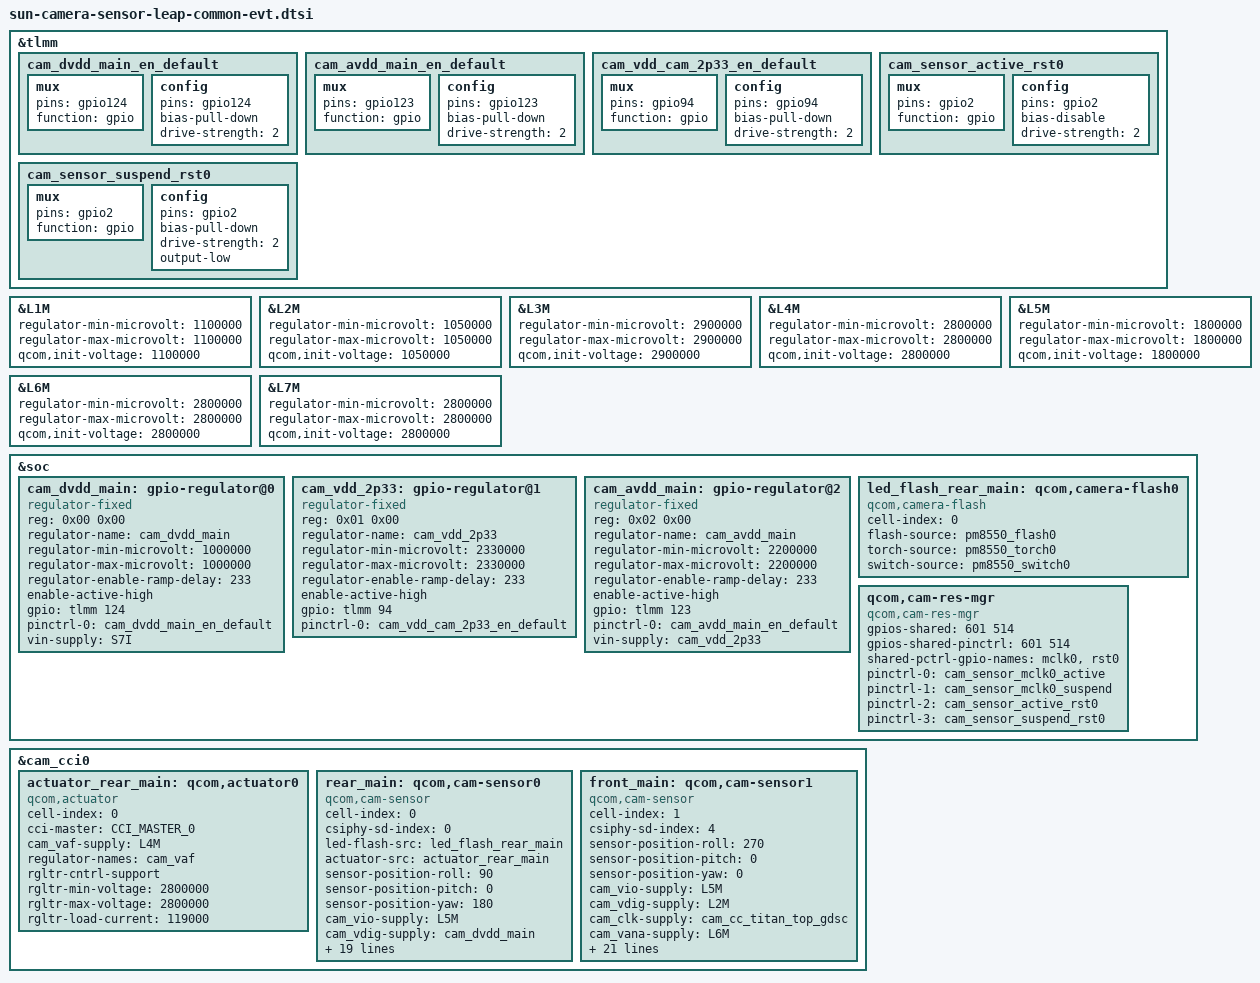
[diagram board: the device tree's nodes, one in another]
#include <dt-bindings/msm-camera.h>

&tlmm {

	cam_dvdd_main_en_default: cam_dvdd_main_en_default {
		mux {
			pins = "gpio124";
			function = "gpio";
		};

		config {
			pins = "gpio124";
			bias-pull-down; /* PULL DOWN */
			drive-strength = <2>; /* 2 MA */
		};
	};

	cam_avdd_main_en_default: cam_avdd_main_en_default {
		mux {
			pins = "gpio123";
			function = "gpio";
		};

		config {
			pins = "gpio123";
			bias-pull-down; /* PULL DOWN */
			drive-strength = <2>; /* 2 MA */
		};
	};

	cam_vdd_cam_2p33_en_default: cam_vdd_cam_2p33_en_default {
		mux {
			pins = "gpio94";
			function = "gpio";
		};

		config {
			pins = "gpio94";
			bias-pull-down; /* PULL DOWN */
			drive-strength = <2>; /* 2 MA */
		};
	};

	cam_sensor_active_rst0: cam_sensor_active_rst0 {
		mux {
			pins = "gpio2";
			function = "gpio";
		};

		config {
			pins = "gpio2";
			bias-disable; /* No PULL */
			drive-strength = <2>; /* 2 MA */
		};
	};

	cam_sensor_suspend_rst0: cam_sensor_suspend_rst0 {
		mux {
			pins = "gpio2";
			function = "gpio";
		};

		config {
			pins = "gpio2";
			bias-pull-down; /* PULL DOWN */
			drive-strength = <2>; /* 2 MA */
			output-low;
		};
	};
};
/*
&L1I {
	regulator-min-microvolt = <1800000>;
	regulator-max-microvolt = <1800000>;
	qcom,init-voltage = <1800000>;
};
*/
&L1M {
	regulator-min-microvolt = <1100000>;
	regulator-max-microvolt = <1100000>;
	qcom,init-voltage = <1100000>;
};

&L2M {
	regulator-min-microvolt = <1050000>;
	regulator-max-microvolt = <1050000>;
	qcom,init-voltage = <1050000>;
};

&L3M {
	regulator-min-microvolt = <2900000>;
	regulator-max-microvolt = <2900000>;
	qcom,init-voltage = <2900000>;
};

&L4M {
	regulator-min-microvolt = <2800000>;
	regulator-max-microvolt = <2800000>;
	qcom,init-voltage = <2800000>;
};

&L5M {
	regulator-min-microvolt = <1800000>;
	regulator-max-microvolt = <1800000>;
	qcom,init-voltage = <1800000>;
};

&L6M {
	regulator-min-microvolt = <2800000>;
	regulator-max-microvolt = <2800000>;
	qcom,init-voltage = <2800000>;
};

&L7M {
	regulator-min-microvolt = <2800000>;
	regulator-max-microvolt = <2800000>;
	qcom,init-voltage = <2800000>;
};

&soc {
	cam_dvdd_main: gpio-regulator@0 {
		compatible = "regulator-fixed";
		reg = <0x00 0x00>;
		regulator-name = "cam_dvdd_main";
		regulator-min-microvolt = <1000000>;
		regulator-max-microvolt = <1000000>;
		regulator-enable-ramp-delay = <233>;
		enable-active-high;
		gpio = <&tlmm 124 0>;
		pinctrl-names = "default";
		pinctrl-0 = <&cam_dvdd_main_en_default>;
		vin-supply = <&S7I>;
	};

	cam_vdd_2p33: gpio-regulator@1 {
		compatible = "regulator-fixed";
		reg = <0x01 0x00>;
		regulator-name = "cam_vdd_2p33";
		regulator-min-microvolt = <2330000>;
		regulator-max-microvolt = <2330000>;
		regulator-enable-ramp-delay = <233>;
		enable-active-high;
		//regulator-always-on;
		gpio = <&tlmm 94 0>;
		pinctrl-names = "default";
		pinctrl-0 = <&cam_vdd_cam_2p33_en_default>;
		//vin-supply = <&BOB1>;
	};

	cam_avdd_main: gpio-regulator@2 {
		compatible = "regulator-fixed";
		reg = <0x02 0x00>;
		regulator-name = "cam_avdd_main";
		regulator-min-microvolt = <2200000>;
		regulator-max-microvolt = <2200000>;
		regulator-enable-ramp-delay = <233>;
		enable-active-high;
		gpio = <&tlmm 123 0>;
		pinctrl-names = "default";
		pinctrl-0 = <&cam_avdd_main_en_default>;
		vin-supply = <&cam_vdd_2p33>;
	};

	led_flash_rear_main: qcom,camera-flash0 {
		cell-index = <0>;
		compatible = "qcom,camera-flash";
		flash-source = <&pm8550_flash0>;
		torch-source = <&pm8550_torch0>;
		switch-source = <&pm8550_switch0>;
		status = "ok";
	};

	qcom,cam-res-mgr {
		compatible = "qcom,cam-res-mgr";
		gpios-shared = <601 514>;
		gpios-shared-pinctrl = <601 514>;
		shared-pctrl-gpio-names = "mclk0", "rst0";
		pinctrl-names = "mclk0_active", "mclk0_suspend", "rst0_active", "rst0_suspend";
		pinctrl-0 = <&cam_sensor_mclk0_active>;
		pinctrl-1 = <&cam_sensor_mclk0_suspend>;
		pinctrl-2 = <&cam_sensor_active_rst0>;
		pinctrl-3 = <&cam_sensor_suspend_rst0>;
		status = "ok";
	};
};

&cam_cci0 {
	actuator_rear_main: qcom,actuator0 {
		cell-index = <0>;
		compatible = "qcom,actuator";
		cci-master = <CCI_MASTER_0>;
		cam_vaf-supply = <&L4M>;
		regulator-names = "cam_vaf";
		rgltr-cntrl-support;
		rgltr-min-voltage = <2800000>;
		rgltr-max-voltage = <2800000>;
		rgltr-load-current = <119000>;
		status = "ok";
	};

	rear_main: qcom,cam-sensor0 {
		cell-index = <0>;
		compatible = "qcom,cam-sensor";
		csiphy-sd-index = <0>;
		//eeprom-src = <&eeprom_rear_main>;
		led-flash-src = <&led_flash_rear_main>;
		actuator-src = <&actuator_rear_main>;
		sensor-position-roll = <90>;
		sensor-position-pitch = <0>;
		sensor-position-yaw = <180>;
		cam_vio-supply = <&L5M>;
		cam_vdig-supply = <&cam_dvdd_main>;
		cam_clk-supply = <&cam_cc_titan_top_gdsc>;
		cam_vana-supply = <&cam_avdd_main>;
		regulator-names = "cam_vio",
			"cam_vdig","cam_clk","cam_vana";
		rgltr-cntrl-support;
		rgltr-min-voltage = <1800000 1000000 0 2200000>;
		rgltr-max-voltage = <1800000 1000000 0 2200000>;
		rgltr-load-current = <101000 787000 0 1000>;
		gpio-no-mux = <0>;
		//pinctrl-names = "cam_default", "cam_suspend";
		//pinctrl-0 = <&cam_sensor_mclk0_active
		//	&cam_sensor_active_rst0>;
		//pinctrl-1 = <&cam_sensor_mclk0_suspend
		//	&cam_sensor_suspend_rst0>;
		gpios = <&tlmm 89 0>,
			<&tlmm 2 0>;
		gpio-reset = <1>;
		gpio-req-tbl-num = <0 1>;
		gpio-req-tbl-flags = <1 0>;
		gpio-req-tbl-label = "CAMIF_MCLK0",
					"CAM_RESET0";
		cci-master = <CCI_MASTER_0>;
		clocks = <&cambistmclkcc CAM_BIST_MCLK_CC_MCLK0_CLK>;
		clock-names = "cam_clk";
		clock-cntl-level = "nominal";
		clock-rates = <24000000>;
		status = "ok";
	};

	front_main: qcom,cam-sensor1 {
		cell-index = <1>;
		compatible = "qcom,cam-sensor";
		csiphy-sd-index = <4>;
		//eeprom-src = <&eeprom_front>;
		sensor-position-roll = <270>;
		sensor-position-pitch = <0>;
		sensor-position-yaw = <0>;
		cam_vio-supply = <&L5M>;
		cam_vdig-supply = <&L2M>;
		cam_clk-supply = <&cam_cc_titan_top_gdsc>;
		cam_vana-supply = <&L6M>;
		regulator-names = "cam_vio", "cam_vdig","cam_clk", "cam_vana";
		rgltr-cntrl-support;
		rgltr-min-voltage = <1800000 1050000 0 2800000>;
		rgltr-max-voltage = <1800000 1050000 0 2800000>;
		rgltr-load-current = <3000 283000 0  50000>;
		gpio-no-mux = <0>;
		pinctrl-names = "cam_default", "cam_suspend";
		pinctrl-0 = <&cam_sensor_mclk4_active
				 &cam_sensor_active_rst4>;
		pinctrl-1 = <&cam_sensor_mclk4_suspend
				 &cam_sensor_suspend_rst4>;
		gpios = <&tlmm 93 0>,
			<&tlmm 7 0>;
		gpio-reset = <1>;
		gpio-req-tbl-num = <0 1>;
		gpio-req-tbl-flags = <1 0>;
		gpio-req-tbl-label = "CAMIF_MCLK4",
					"CAM_RESET4";
		cci-master = <CCI_MASTER_1>;
		clocks = <&cambistmclkcc CAM_BIST_MCLK_CC_MCLK4_CLK>;
		clock-names = "cam_clk";
		clock-cntl-level = "nominal";
		clock-rates = <24000000>;
		status = "ok";
	};
};
/*
&qupv3_se9_i2c {
	status = "ok";
	qcom,high-perf;
	qcom,clk-freq-out = <1000000>;
	qcom,pm-ctrl-client;

	front_main: qcom,cam-sensor1 {
		cell-index = <1>;
		reg = <0x2d>;
		compatible = "qcom,cam-i2c-sensor";
		csiphy-sd-index = <4>;
		sensor-position-roll = <270>;
		sensor-position-pitch = <0>;
		sensor-position-yaw = <0>;
		cam_vio-supply = <&L1I>;
		cam_vdig-supply = <&L2N>;
		cam_clk-supply = <&cam_cc_titan_top_gdsc>;
		cam_vana-supply = <&L6N>;
		regulator-names = "cam_vio", "cam_vdig","cam_clk", "cam_vana";
		rgltr-cntrl-support;
		aon-camera-id = <AON_CAM1>;
		rgltr-min-voltage = <1800000 1000000 0 2200000>;
		rgltr-max-voltage = <1800000 1000000 0 2200000>;
		rgltr-load-current = <3000 283000 0  50000>;
		gpio-no-mux = <0>;
		pinctrl-names = "cam_default", "cam_suspend";
		pinctrl-0 = <&cam_sensor_mclk4_active
				 &cam_sensor_active_rst4>;
		pinctrl-1 = <&cam_sensor_mclk4_suspend
				 &cam_sensor_suspend_rst4>;
		gpios = <&tlmm 93 0>,
			<&tlmm 7 0>;
		gpio-reset = <1>;
		gpio-req-tbl-num = <0 1>;
		gpio-req-tbl-flags = <1 0>;
		gpio-req-tbl-label = "CAMIF_MCLK4",
					"CAM_RESET4";
		clocks = <&cambistmclkcc CAM_BIST_MCLK_CC_MCLK4_CLK>;
		clock-names = "cam_clk";
		clock-cntl-level = "nominal";
		clock-rates = <19200000>;
		status = "ok";
	};
};
*/
